AUTOSAR XML (schema 00049)
package /ISOFT/PlatformComponents/ucm_master
  process design ucmm_design: executable=ucmmd
package /ISOFT/PlatformComponents/ucm_master/exe
  executable ucmmd: category=PLATFORM_LEVEL, build-type=BUILD-TYPE-DEBUG, logging-behavior=USES-LOGGING, minimum-timer-granularity=1000.0, reporting-behavior=REPORTS-EXECUTION-STATE, version=1.0.0
    root sw component prototype ucmm_root: application-type=ucm_master
package /ISOFT/PlatformComponents/ucm_master/swc
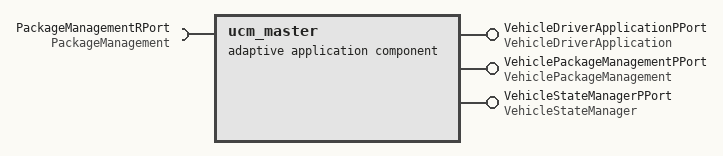
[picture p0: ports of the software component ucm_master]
  adaptive application sw component type ucm_master
    require port PackageManagementRPort: required-interface=PackageManagement
    provide/require port SwPackageTransferStatusPRPort: provided-required-interface=SwPackageTransferStatus
    provide/require port CampaignHistoryPRPort: provided-required-interface=CampaignHistory
    provide port VehicleDriverApplicationPPort: provided-interface=VehicleDriverApplication
    provide port VehiclePackageManagementPPort: provided-interface=VehiclePackageManagement
    provide port VehicleStateManagerPPort: provided-interface=VehicleStateManager
